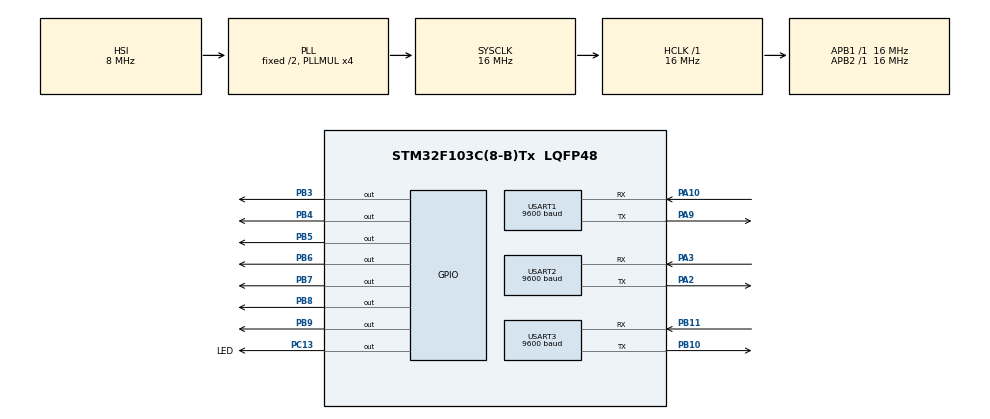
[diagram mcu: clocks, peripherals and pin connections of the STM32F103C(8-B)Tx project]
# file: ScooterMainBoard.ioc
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Dma.Request0=USART2_RX
Dma.Request1=USART3_RX
Dma.USART2_RX.0.Direction=DMA_PERIPH_TO_MEMORY
Dma.USART2_RX.0.Instance=DMA1_Channel6
Dma.USART2_RX.0.MemDataAlignment=DMA_MDATAALIGN_BYTE
Dma.USART2_RX.0.MemInc=DMA_MINC_ENABLE
Dma.USART2_RX.0.Mode=DMA_NORMAL
Dma.USART2_RX.0.PeriphDataAlignment=DMA_PDATAALIGN_BYTE
Dma.USART2_RX.0.PeriphInc=DMA_PINC_DISABLE
Dma.USART2_RX.0.Priority=DMA_PRIORITY_LOW
Dma.USART3_RX.1.Direction=DMA_PERIPH_TO_MEMORY
Dma.USART3_RX.1.Instance=DMA1_Channel3
Dma.USART3_RX.1.MemDataAlignment=DMA_MDATAALIGN_BYTE
Dma.USART3_RX.1.MemInc=DMA_MINC_ENABLE
Dma.USART3_RX.1.Mode=DMA_NORMAL
Dma.USART3_RX.1.PeriphDataAlignment=DMA_PDATAALIGN_BYTE
Dma.USART3_RX.1.PeriphInc=DMA_PINC_DISABLE
Dma.USART3_RX.1.Priority=DMA_PRIORITY_LOW
Mcu.Family=STM32F1
Mcu.Name=STM32F103C(8-B)Tx
Mcu.Package=LQFP48
NVIC.DMA1_Channel3_IRQn=true\:0\:0\:false\:false\:true\:false\:true
NVIC.DMA1_Channel6_IRQn=true\:0\:0\:false\:false\:true\:false\:true
NVIC.PriorityGroup=NVIC_PRIORITYGROUP_4
NVIC.USART1_IRQn=true\:0\:0\:false\:false\:true\:true\:true
PA10.Mode=Asynchronous
PA10.Signal=USART1_RX
PA13.Mode=Serial_Wire
PA13.Signal=SYS_JTMS-SWDIO
PA14.Mode=Serial_Wire
PA14.Signal=SYS_JTCK-SWCLK
PA2.Mode=Asynchronous
PA2.Signal=USART2_TX
PA3.Mode=Asynchronous
PA3.Signal=USART2_RX
PA9.Mode=Asynchronous
PA9.Signal=USART1_TX
PB10.Mode=Asynchronous
PB10.Signal=USART3_TX
PB11.Mode=Asynchronous
PB11.Signal=USART3_RX
PB3.Signal=GPIO_Output
PB4.Signal=GPIO_Output
PB5.Signal=GPIO_Output
PB6.Signal=GPIO_Output
PB7.Signal=GPIO_Output
PB8.Signal=GPIO_Output
PB9.Signal=GPIO_Output
PC13-TAMPER-RTC.GPIO_Label=LED
PC13-TAMPER-RTC.Signal=GPIO_Output
ProjectManager.HeapSize=0x200
ProjectManager.StackSize=0x400
ProjectManager.TargetToolchain=STM32CubeIDE
RCC.AHBFreq_Value=16000000
RCC.APB1Freq_Value=16000000
RCC.APB1TimFreq_Value=16000000
RCC.APB2Freq_Value=16000000
RCC.APB2TimFreq_Value=16000000
RCC.HCLKFreq_Value=16000000
RCC.PLLMUL=RCC_PLL_MUL4
RCC.SYSCLKFreq_VALUE=16000000
RCC.SYSCLKSource=RCC_SYSCLKSOURCE_PLLCLK
RCC.USBFreq_Value=16000000
USART1.BaudRate=9600
USART1.VirtualMode=VM_ASYNC
USART2.BaudRate=9600
USART2.VirtualMode=VM_ASYNC
USART3.BaudRate=9600
USART3.VirtualMode=VM_ASYNC
board=custom

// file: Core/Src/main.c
/* USER CODE BEGIN Header */
/**
  ******************************************************************************
  * @file           : main.c
  * @brief          : Main program body
  ******************************************************************************
  * @attention
  *
  * Copyright (c) 2022 STMicroelectronics.
  * All rights reserved.
  *
  * This software is licensed under terms that can be found in the LICENSE file
  * in the root directory of this software component.
  * If no LICENSE file comes with this software, it is provided AS-IS.
  *
  ******************************************************************************
  */
/* USER CODE END Header */
#include "main.h"

/* USER CODE BEGIN Includes */
#include "APP.h"
/* USER CODE END Includes */

UART_HandleTypeDef huart1;
UART_HandleTypeDef huart2;
UART_HandleTypeDef huart3;
DMA_HandleTypeDef hdma_usart2_rx;
DMA_HandleTypeDef hdma_usart3_rx;

void SystemClock_Config(void);
static void MX_GPIO_Init(void);
static void MX_USART1_UART_Init(void);
static void MX_DMA_Init(void);
static void MX_USART2_UART_Init(void);
static void MX_USART3_UART_Init(void);

int main(void)
{

  /* MCU Configuration--------------------------------------------------------*/

  /* Reset of all peripherals, Initializes the Flash interface and the Systick. */
  HAL_Init();

  /* Configure the system clock */
  SystemClock_Config();

  /* Initialize all configured peripherals */
  MX_GPIO_Init();
  MX_USART1_UART_Init();
  MX_DMA_Init();
  MX_USART2_UART_Init();
  MX_USART3_UART_Init();
  /* USER CODE BEGIN 2 */
  APP_init();
  /* USER CODE END 2 */

  /* Infinite loop */
  /* USER CODE BEGIN WHILE */
  while (1)
  {
	  APP_while();

//	  HAL_GPIO_TogglePin(LED_GPIO_Port, LED_Pin);
	  HAL_Delay(1000);
    /* USER CODE END WHILE */

  }
}

void SystemClock_Config(void)
{
  RCC_OscInitTypeDef RCC_OscInitStruct = {0};
  RCC_ClkInitTypeDef RCC_ClkInitStruct = {0};

  /** Initializes the RCC Oscillators according to the specified parameters
  * in the RCC_OscInitTypeDef structure.
  */
  RCC_OscInitStruct.OscillatorType = RCC_OSCILLATORTYPE_HSI;
  RCC_OscInitStruct.HSIState = RCC_HSI_ON;
  RCC_OscInitStruct.HSICalibrationValue = RCC_HSICALIBRATION_DEFAULT;
  RCC_OscInitStruct.PLL.PLLState = RCC_PLL_ON;
  RCC_OscInitStruct.PLL.PLLSource = RCC_PLLSOURCE_HSI_DIV2;
  RCC_OscInitStruct.PLL.PLLMUL = RCC_PLL_MUL4;
  if (HAL_RCC_OscConfig(&RCC_OscInitStruct) != HAL_OK)
  {
    Error_Handler();
  }
  /** Initializes the CPU, AHB and APB buses clocks
  */
  RCC_ClkInitStruct.ClockType = RCC_CLOCKTYPE_HCLK|RCC_CLOCKTYPE_SYSCLK
                              |RCC_CLOCKTYPE_PCLK1|RCC_CLOCKTYPE_PCLK2;
  RCC_ClkInitStruct.SYSCLKSource = RCC_SYSCLKSOURCE_PLLCLK;
  RCC_ClkInitStruct.AHBCLKDivider = RCC_SYSCLK_DIV1;
  RCC_ClkInitStruct.APB1CLKDivider = RCC_HCLK_DIV1;
  RCC_ClkInitStruct.APB2CLKDivider = RCC_HCLK_DIV1;

  if (HAL_RCC_ClockConfig(&RCC_ClkInitStruct, FLASH_LATENCY_0) != HAL_OK)
  {
    Error_Handler();
  }
}

static void MX_USART1_UART_Init(void)
{

  huart1.Instance = USART1;
  huart1.Init.BaudRate = 9600;
  huart1.Init.WordLength = UART_WORDLENGTH_8B;
  huart1.Init.StopBits = UART_STOPBITS_1;
  huart1.Init.Parity = UART_PARITY_NONE;
  huart1.Init.Mode = UART_MODE_TX_RX;
  huart1.Init.HwFlowCtl = UART_HWCONTROL_NONE;
  huart1.Init.OverSampling = UART_OVERSAMPLING_16;
  if (HAL_UART_Init(&huart1) != HAL_OK)
  {
    Error_Handler();
  }

}

static void MX_USART2_UART_Init(void)
{

  huart2.Instance = USART2;
  huart2.Init.BaudRate = 9600;
  huart2.Init.WordLength = UART_WORDLENGTH_8B;
  huart2.Init.StopBits = UART_STOPBITS_1;
  huart2.Init.Parity = UART_PARITY_NONE;
  huart2.Init.Mode = UART_MODE_TX_RX;
  huart2.Init.HwFlowCtl = UART_HWCONTROL_NONE;
  huart2.Init.OverSampling = UART_OVERSAMPLING_16;
  if (HAL_UART_Init(&huart2) != HAL_OK)
  {
    Error_Handler();
  }

}

static void MX_USART3_UART_Init(void)
{

  huart3.Instance = USART3;
  huart3.Init.BaudRate = 9600;
  huart3.Init.WordLength = UART_WORDLENGTH_8B;
  huart3.Init.StopBits = UART_STOPBITS_1;
  huart3.Init.Parity = UART_PARITY_NONE;
  huart3.Init.Mode = UART_MODE_TX_RX;
  huart3.Init.HwFlowCtl = UART_HWCONTROL_NONE;
  huart3.Init.OverSampling = UART_OVERSAMPLING_16;
  if (HAL_UART_Init(&huart3) != HAL_OK)
  {
    Error_Handler();
  }

}

static void MX_DMA_Init(void)
{

  /* DMA controller clock enable */
  __HAL_RCC_DMA1_CLK_ENABLE();

  /* DMA interrupt init */
  /* DMA1_Channel3_IRQn interrupt configuration */
  HAL_NVIC_SetPriority(DMA1_Channel3_IRQn, 0, 0);
  HAL_NVIC_EnableIRQ(DMA1_Channel3_IRQn);
  /* DMA1_Channel6_IRQn interrupt configuration */
  HAL_NVIC_SetPriority(DMA1_Channel6_IRQn, 0, 0);
  HAL_NVIC_EnableIRQ(DMA1_Channel6_IRQn);

}

static void MX_GPIO_Init(void)
{
  GPIO_InitTypeDef GPIO_InitStruct = {0};

  /* GPIO Ports Clock Enable */
  __HAL_RCC_GPIOC_CLK_ENABLE();
  __HAL_RCC_GPIOA_CLK_ENABLE();
  __HAL_RCC_GPIOB_CLK_ENABLE();

  /*Configure GPIO pin Output Level */
  HAL_GPIO_WritePin(LED_GPIO_Port, LED_Pin, GPIO_PIN_RESET);

  /*Configure GPIO pin Output Level */
  HAL_GPIO_WritePin(GPIOB, GPIO_PIN_3|GPIO_PIN_4|GPIO_PIN_5|GPIO_PIN_6
                          |GPIO_PIN_7|GPIO_PIN_8|GPIO_PIN_9, GPIO_PIN_RESET);

  /*Configure GPIO pin : LED_Pin */
  GPIO_InitStruct.Pin = LED_Pin;
  GPIO_InitStruct.Mode = GPIO_MODE_OUTPUT_PP;
  GPIO_InitStruct.Pull = GPIO_NOPULL;
  GPIO_InitStruct.Speed = GPIO_SPEED_FREQ_LOW;
  HAL_GPIO_Init(LED_GPIO_Port, &GPIO_InitStruct);

  /*Configure GPIO pins : PB3 PB4 PB5 PB6
                           PB7 PB8 PB9 */
  GPIO_InitStruct.Pin = GPIO_PIN_3|GPIO_PIN_4|GPIO_PIN_5|GPIO_PIN_6
                          |GPIO_PIN_7|GPIO_PIN_8|GPIO_PIN_9;
  GPIO_InitStruct.Mode = GPIO_MODE_OUTPUT_PP;
  GPIO_InitStruct.Pull = GPIO_NOPULL;
  GPIO_InitStruct.Speed = GPIO_SPEED_FREQ_LOW;
  HAL_GPIO_Init(GPIOB, &GPIO_InitStruct);

}

void Error_Handler(void)
{
  __disable_irq();
  while (1)
  {
  }
}
